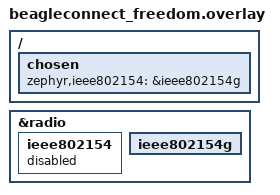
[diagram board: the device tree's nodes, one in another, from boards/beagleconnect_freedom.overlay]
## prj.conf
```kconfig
# SPDX-License-Identifier: Apache-2.0

# Increased main stack size required for initialization
CONFIG_MAIN_STACK_SIZE=4096

# Enable Networking and OpenThread stack
CONFIG_NETWORKING=y

CONFIG_NET_L2_IEEE802154=y


CONFIG_IEEE802154=y

CONFIG_IEEE802154_CC13XX_CC26XX=y

# Use NVS as settings backend
CONFIG_NVS=y

# Logging
CONFIG_LOG=y
CONFIG_NET_LOG=y
CONFIG_LOG_PRINTK=y

# Networking and OpenThread shells
CONFIG_SHELL=y
CONFIG_NET_SHELL=y




# Enable Zephyr’s Settings subsystem
CONFIG_SETTINGS=y

# Use the NVS (non-volatile storage) back end
CONFIG_SETTINGS_NVS=y

# Ensure runtime APIs are available
CONFIG_SETTINGS_RUNTIME=y


CONFIG_NET_L2_IEEE802154_SHELL=y
```

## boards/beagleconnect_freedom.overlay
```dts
/* beagleconnect_freedom.overlay */

/ {
    chosen {
        zephyr,ieee802154     = &ieee802154g;
    };
};

&radio {
    status = "okay";

    ieee802154 {
        status = "disabled";
    };

    ieee802154g {
        status = "okay";
    };
};
```

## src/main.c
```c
#include <zephyr/kernel.h>
#include <zephyr/drivers/gpio.h>

#define SLEEP_MS 500
#define LED_NODE DT_ALIAS(led0)
static const struct gpio_dt_spec led = GPIO_DT_SPEC_GET(LED_NODE, gpios);

int main(void)
{
    printk("Port: %s\n", led.port->name);
    gpio_pin_configure_dt(&led, GPIO_OUTPUT_ACTIVE);
    while (1) {
        gpio_pin_toggle_dt(&led);
        k_msleep(SLEEP_MS);
    }
	return 0;
}
```
